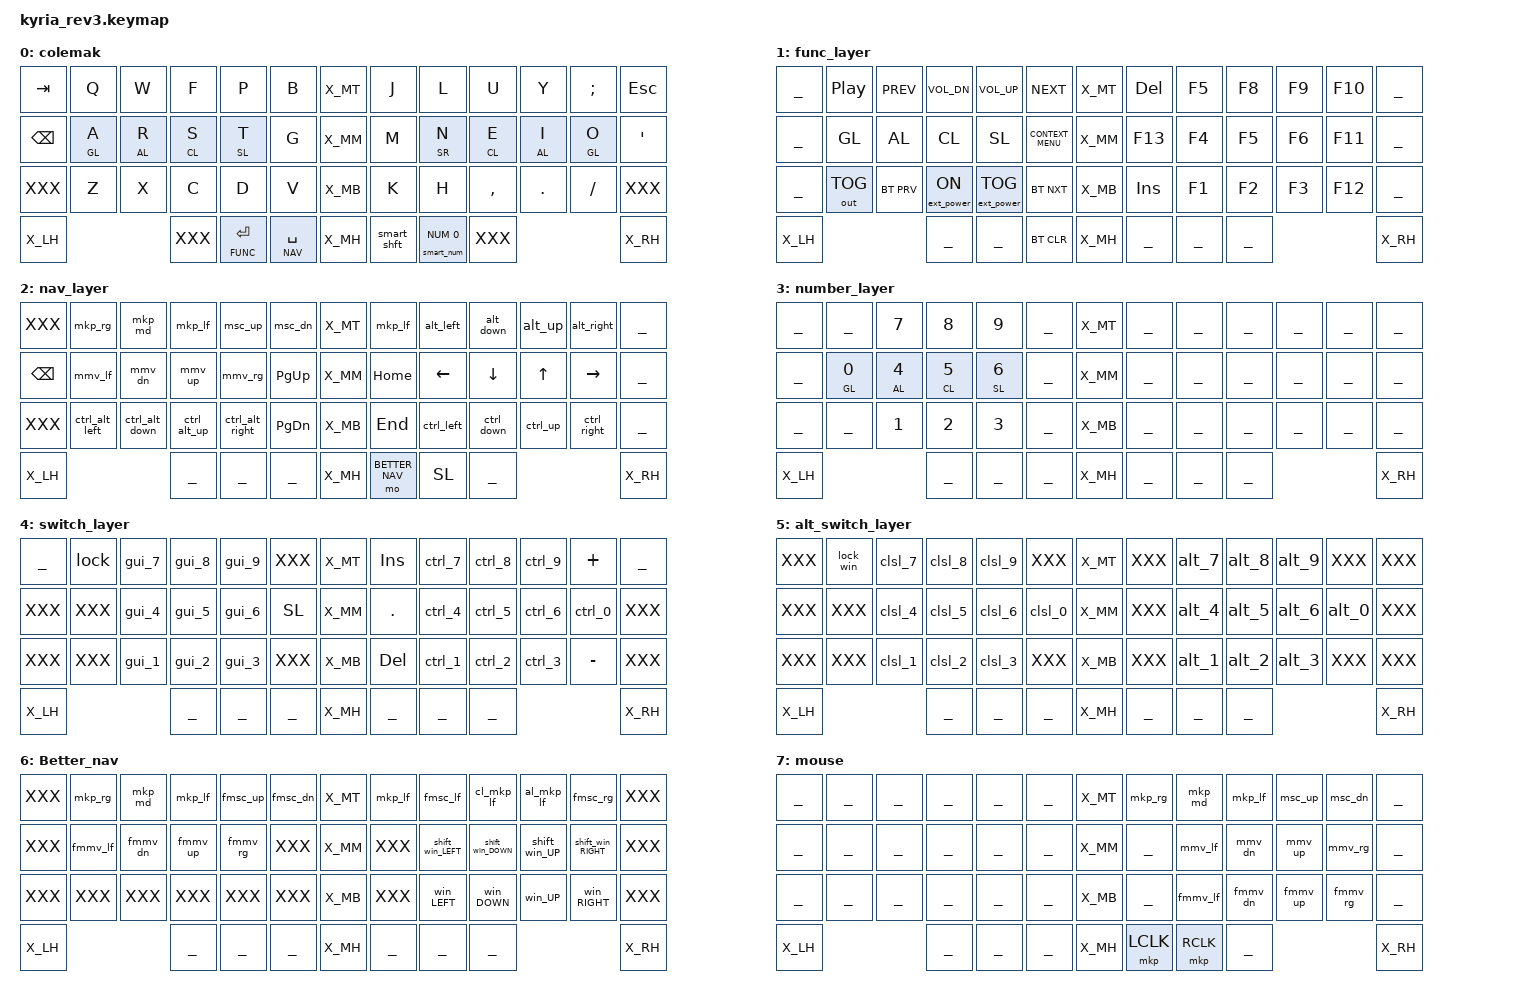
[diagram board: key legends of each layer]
/*      
 * Copyright (c) 2023 The ZMK Contributors
 *      vim.api.nvim_create_autocmd({ "BufRead", "BufNewFile" }, {
  pattern = "*.keymap",
  command = "set filetype=cpp",
})

 * SPDX-License-Identifier: MIT
 */

#include <behaviors.dtsi>
#include <dt-bindings/zmk/keys.h>
#include <dt-bindings/zmk/bt.h>
#include <dt-bindings/zmk/outputs.h>
#include <dt-bindings/zmk/mouse.h>
#include <dt-bindings/zmk/ext_power.h>
#include "extra_keys.h"

#include <dt-bindings/zmk/rgb.h>
#include "constants.h"
#define HOST_OS LINUX // Needed for unicode international_chars

#include "../zmk-nodefree-config/helper.h"
#include "../layouts/col_main.dtsi"
#include "../behaviors/combos_50.dtsi"
#include "../behaviors/hold-tap.dtsi"
#include "../behaviors/macros.dtsi"
#include "../behaviors/mod-morph.dtsi"
#include "../behaviors/mouse.dtsi"

/* map kyria's extra keys */
#define X_MT                    // top row, middle
#define X_MM                    // middle row, middle
#define X_MB  XXX XXX XXX XXX                 // bottom row, middle
#define X_LH  XXX XXX  // thumb row, left
#define X_RH  XXX XXX          // thumb row, right
/* Nav cluster */

// long-tap action on hold, short-tap action on all interrupts
#define MT_CORE \
    flavor = "tap-preferred"; \
    tapping-term-ms = <220>; \
    quick-tap-ms = <220>; \
    hold-trigger-key-positions = <0>;

&mt { MT_CORE };
ZMK_BEHAVIOR(mt_home, hold_tap, bindings = <&masked_home>, <&kp>; MT_CORE)
ZMK_BEHAVIOR(mt_end,  hold_tap,  bindings = <&masked_end>, <&kp>; MT_CORE)

#define NAV_LEFT  &mt_home 0   LEFT    // tap: left  | long-tap: beginning of line
#define NAV_RIGHT &mt_end 0    RIGHT   // tap: right | long-tap: end       of line
#define NAV_UP    &mt LC(HOME) UP      // tap: up    | long-tap: beginning of document
#define NAV_DOWN  &mt LC(END)  DOWN    // tap: down  | long-tap: end       of document
#define NAV_BSPC  &mt LC(BSPC) BSPC    // tap: bspc  | long-tap: delete word backward
#define NAV_DEL   &mt LC(DEL)  DEL     // tap: del   | long-tap: delete word forward

// mask CTRL when holding left/right to avoid accidental jumps to beginning/end of document
#define MASK_MODS(NAME, MODS, BINDING) \
    ZMK_BEHAVIOR(NAME, mod_morph, \
        bindings = <BINDING>, <BINDING>; \
        mods = <MODS>; \
    )
MASK_MODS(masked_home, (MOD_LCTL), &kp HOME)
MASK_MODS(masked_end,  (MOD_LCTL), &kp END)



/* Global settings */


&sk {  // sticky-key config
    release-after-ms = <900>;  // release after 0.6s
    quick-release;             // no double capitalization when rolling keys
};

&sl {  // sticky-layer config
    ignore-modifiers;          // allow chording sticky mods & layers
};


/* Homerow mods */

#define KEYS_L LT0 LT1 LT2 LT3 LT4 LM0 LM1 LM2 LM3 LM4 LB0 LB1 LB2 LB3 LB4  // left hand
#define KEYS_R RT0 RT1 RT2 RT3 RT4 RM0 RM1 RM2 RM3 RM4 RB0 RB1 RB2 RB3 RB4  // right hand
#define THUMBS LH2 LH1 LH0 RH0 RH1 RH2                                      // thumbs




#define QUICK_TAP_MS 175

&num_word {  // num-word, requires PR #1451
    layers = <NUM>;
    continue-list = <BSPC DEL DOT COMMA PLUS MINUS STAR FSLH EQUAL>;
};


ZMK_BEHAVIOR(num_dance, tap_dance,
    tapping-term-ms = <200>;
    bindings = <&num_word>, <&sl NUM>;  // reverse this for sticky-num on single tap
)

#define SMART_NUM &smart_num NUM 0
#// tap: num-word | double-tap: sticky num-layer | hold: num-layer
ZMK_BEHAVIOR(smart_num, hold_tap,
    flavor = "balanced";
    tapping-term-ms = <200>;
    quick-tap-ms = <QUICK_TAP_MS>;
    bindings = <&mo>, <&num_dance>;
)


ZMK_LAYER(colemak,
//╭──────╮ ╭─────────────┬─────────────┬─────────────┬─────────────┬─────────────╮ ╭──────╮ ╭─────────────┬─────────────┬─────────────┬─────────────┬─────────────╮ ╭──────╮
 &kp TAB     &kp Q         &kp W         &kp F         &kp P         &kp B           X_MT        &kp J       &kp L         &kp U        &kp Y         &kp SEMI      &kp ESC
//├──────┤ ├─────────────┼─────────────┼─────────────┼─────────────┼─────────────┤ ├──────┤ ├─────────────┼─────────────┼─────────────┼─────────────┼─────────────┤ ├──────┤
&kp BSPC    &hml GL A    &hml AL R      &hml CL S      &hml SL T     &kp G           X_MM        &kp M       &hmr SR N     &hmr CL E    &hmr AL I     &hml GL O     &kp SQT 
//├──────┤ ├─────────────┼─────────────┼─────────────┼─────────────┼─────────────┤ ├──────┤ ├─────────────┼─────────────┼─────────────┼─────────────┼─────────────┤ ├──────┤
    XXX         &kp Z        &kp X       &kp C         &kp D         &kp V           X_MB        &kp K       &kp H         &kp COMMA     &kp DOT      &kp FSLH        XXX
//├──────┤ ╰─────────────┼─────────────┴─────────────┼─────────────┼─────────────┤ ├──────┤ ├─────────────┼─────────────┼─────────────┴───────────────────────────╯ ├──────┤
    X_LH                                 XXX        &lt FUNC RETURN &lt NAV SPACE    X_MH      &smart_shft   SMART_NUM    XXX                                         X_RH
//╰──────╯                                           ╰─────────────┴─────────────╯ ╰──────╯ ╰─────────────┴─────────────╯                                           ╰──────╯
)


ZMK_LAYER(func_layer,
//╭──────╮ ╭─────────────┬─────────────┬─────────────┬─────────────┬─────────────╮ ╭──────╮ ╭─────────────┬─────────────┬─────────────┬─────────────┬─────────────╮ ╭──────╮
    ___     &kp C_PP       &kp C_PREV    &kp C_VOL_DN  &kp C_VOL_UP  &kp C_NEXT     X_MT      &kp DEL       &kp F5          &kp F8        &kp F9        &kp F10       ___
//├──────┤ ├─────────────┼─────────────┼─────────────┼─────────────┼─────────────┤ ├──────┤ ├─────────────┼─────────────┼─────────────┼─────────────┼─────────────┤ ├──────┤
    ___     &kp GL          &kp AL       &kp CL        &kp SL   &kp K_CONTEXT_MENU  X_MM      &kp F13       &kp F4          &kp F5        &kp F6        &kp F11       ___        
//├──────┤ ├─────────────┼─────────────┼─────────────┼─────────────┼─────────────┤ ├──────┤ ├─────────────┼─────────────┼─────────────┼─────────────┼─────────────┤ ├──────┤
    ___   &out OUT_TOG &bt BT_PRV   &ext_power EP_ON &ext_power EP_TOG &bt BT_NXT    X_MB      &kp INS       &kp F1          &kp F2        &kp F3        &kp F12       ___
//├──────┤ ╰─────────────┼─────────────┴─────────────┼─────────────┼─────────────┤ ├──────┤ ├─────────────┼─────────────┼─────────────┴───────────────────────────╯ ├──────┤
    X_LH                                ___           ___           &bt BT_CLR      X_MH       ___          ___           ___                                         X_RH
//╰──────╯                                           ╰─────────────┴─────────────╯ ╰──────╯ ╰─────────────┴─────────────╯                                           ╰──────╯
)

ZMK_LAYER(nav_layer,
//╭──────╮ ╭─────────────┬─────────────┬─────────────┬─────────────┬─────────────╮ ╭──────╮ ╭─────────────┬─────────────┬─────────────┬─────────────┬─────────────╮ ╭──────╮
    XXX      &mkp_rg        &mkp_md      &mkp_lf        &msc_up       &msc_dn        X_MT       &mkp_lf       &alt_left    &alt_down     &alt_up      &alt_right      ___
//├──────┤ ├─────────────┼─────────────┼─────────────┼─────────────┼─────────────┤ ├──────┤ ├─────────────┼─────────────┼─────────────┼─────────────┼─────────────┤ ├──────┤
&kp BSPC     &mmv_lf        &mmv_dn      &mmv_up        &mmv_rg       &kp PG_UP      X_MM    &kp HOME      &kp LEFT     &kp DOWN      &kp UP       &kp RIGHT       ___
//├──────┤ ├─────────────┼─────────────┼─────────────┼─────────────┼─────────────┤ ├──────┤ ├─────────────┼─────────────┼─────────────┼─────────────┼─────────────┤ ├──────┤
    XXX     &ctrl_alt_left &ctrl_alt_down &ctrl_alt_up &ctrl_alt_right &kp PG_DN     X_MB       &kp END       &ctrl_left   &ctrl_down    &ctrl_up     &ctrl_right     ___
//├──────┤ ╰─────────────┼─────────────┴─────────────┼─────────────┼─────────────┤ ├──────┤ ├─────────────┼─────────────┼─────────────┴───────────────────────────╯ ├──────┤
    X_LH                                ___           ___             ___            X_MH   &mo BETTER_NAV    &kp SL           ___                                    X_RH
//╰──────╯                                           ╰─────────────┴─────────────╯ ╰──────╯ ╰─────────────┴─────────────╯                                           ╰──────╯
)

                    
ZMK_LAYER(number_layer,
//╭──────╮ ╭─────────────┬─────────────┬─────────────┬─────────────┬─────────────╮ ╭──────╮ ╭─────────────┬─────────────┬─────────────┬─────────────┬─────────────╮ ╭──────╮
    ___          ___        &kp N7       &kp N8         &kp N9        ___            X_MT          ___           ___           ___           ___        ___           ___        
//├──────┤ ├─────────────┼─────────────┼─────────────┼─────────────┼─────────────┤ ├──────┤ ├─────────────┼─────────────┼─────────────┼─────────────┼─────────────┤ ├──────┤
    ___        &hml GL N0 &hml AL N4    &hml CL N5     &hml SL N6     ___            X_MM          ___           ___           ___           ___        ___           ___        
//├──────┤ ├─────────────┼─────────────┼─────────────┼─────────────┼─────────────┤ ├──────┤ ├─────────────┼─────────────┼─────────────┼─────────────┼─────────────┤ ├──────┤
    ___          ___        &kp N1      &kp N2         &kp N3         ___            X_MB          ___           ___           ___           ___        ___           ___   
//├──────┤ ╰─────────────┼─────────────┴─────────────┼─────────────┼─────────────┤ ├──────┤ ├─────────────┼─────────────┼─────────────┴───────────────────────────╯ ├──────┤
    X_LH                                ___           ___             ___            X_MH          ___           ___           ___                                    X_RH
//╰──────╯                                           ╰─────────────┴─────────────╯ ╰──────╯ ╰─────────────┴─────────────╯                                           ╰──────╯
)


ZMK_LAYER(switch_layer,
//╭──────╮ ╭─────────────┬─────────────┬─────────────┬─────────────┬─────────────╮ ╭──────╮ ╭─────────────┬─────────────┬─────────────┬─────────────┬─────────────╮ ╭──────╮
    ___         &lock       &gui_7       &gui_8         &gui_9        XXX            X_MT        &kp INS     &ctrl_7      &ctrl_8       &ctrl_9       &kp PLUS        ___
//├──────┤ ├─────────────┼─────────────┼─────────────┼─────────────┼─────────────┤ ├──────┤ ├─────────────┼─────────────┼─────────────┼─────────────┼─────────────┤ ├──────┤
    XXX         XXX         &gui_4       &gui_5         &gui_6       &kp SL          X_MM        &kp DOT     &ctrl_4       &ctrl_5         &ctrl_6        &ctrl_0     XXX
//├──────┤ ├─────────────┼─────────────┼─────────────┼─────────────┼─────────────┤ ├──────┤ ├─────────────┼─────────────┼─────────────┼─────────────┼─────────────┤ ├──────┤
    XXX         XXX         &gui_1       &gui_2         &gui_3        XXX            X_MB        &kp DEL     &ctrl_1       &ctrl_2      &ctrl_3       &kp MINUS       XXX
//├──────┤ ╰─────────────┼─────────────┴─────────────┼─────────────┼─────────────┤ ├──────┤ ├─────────────┼─────────────┼─────────────┴───────────────────────────╯ ├──────┤
    X_LH                                ___           ___             ___            X_MH          ___           ___           ___                                    X_RH
//╰──────╯                                           ╰─────────────┴─────────────╯ ╰──────╯ ╰─────────────┴─────────────╯                                           ╰──────╯
)


ZMK_LAYER(alt_switch_layer,
//╭──────╮ ╭─────────────┬─────────────┬─────────────┬─────────────┬─────────────╮ ╭──────╮ ╭─────────────┬─────────────┬─────────────┬─────────────┬─────────────╮ ╭──────╮
    XXX       &lock_win     &clsl_7      &clsl_8        &clsl_9       XXX            X_MT        XXX         &alt_7       &alt_8        &alt_9        XXX             XXX           
//├──────┤ ├─────────────┼─────────────┼─────────────┼─────────────┼─────────────┤ ├──────┤ ├─────────────┼─────────────┼─────────────┼─────────────┼─────────────┤ ├──────┤
    XXX       XXX           &clsl_4      &clsl_5        &clsl_6      &clsl_0         X_MM        XXX         &alt_4      &alt_5         &alt_6        &alt_0          XXX             
//├──────┤ ├─────────────┼─────────────┼─────────────┼─────────────┼─────────────┤ ├──────┤ ├─────────────┼─────────────┼─────────────┼─────────────┼─────────────┤ ├──────┤
    XXX       XXX           &clsl_1      &clsl_2        &clsl_3      XXX             X_MB        XXX         &alt_1      &alt_2         &alt_3        XXX             XXX             
//├──────┤ ╰─────────────┼─────────────┴─────────────┼─────────────┼─────────────┤ ├──────┤ ├─────────────┼─────────────┼─────────────┴───────────────────────────╯ ├──────┤
    X_LH                                ___           ___             ___            X_MH          ___           ___           ___                                    X_RH
//╰──────╯                                           ╰─────────────┴─────────────╯ ╰──────╯ ╰─────────────┴─────────────╯                                           ╰──────╯
)


ZMK_LAYER(Better_nav,
//╭──────╮ ╭─────────────┬─────────────┬─────────────┬─────────────┬─────────────╮ ╭──────╮ ╭─────────────┬─────────────┬─────────────┬─────────────┬─────────────╮ ╭──────╮
    XXX       &mkp_rg       &mkp_md      &mkp_lf        &fmsc_up      &fmsc_dn       X_MT       &mkp_lf      &fmsc_lf     &cl_mkp_lf    &al_mkp_lf    &fmsc_rg        XXX
//├──────┤ ├─────────────┼─────────────┼─────────────┼─────────────┼─────────────┤ ├──────┤ ├─────────────┼─────────────┼─────────────┼─────────────┼─────────────┤ ├──────┤
    XXX       &fmmv_lf      &fmmv_dn     &fmmv_up       &fmmv_rg     XXX             X_MM        XXX     &shift_win_LEFT &shift_win_DOWN &shift_win_UP &shift_win_RIGHT XXX
//├──────┤ ├─────────────┼─────────────┼─────────────┼─────────────┼─────────────┤ ├──────┤ ├─────────────┼─────────────┼─────────────┼─────────────┼─────────────┤ ├──────┤
    XXX       XXX           XXX          XXX            XXX          XXX             X_MB        XXX          &win_LEFT    &win_DOWN      &win_UP     &win_RIGHT      XXX
//├──────┤ ╰─────────────┼─────────────┴─────────────┼─────────────┼─────────────┤ ├──────┤ ├─────────────┼─────────────┼─────────────┴───────────────────────────╯ ├──────┤
    X_LH                                ___           ___             ___            X_MH          ___           ___           ___                                    X_RH
//╰──────╯                                           ╰─────────────┴─────────────╯ ╰──────╯ ╰─────────────┴─────────────╯                                           ╰──────╯
)

ZMK_LAYER(mouse,
//╭──────╮ ╭─────────────┬─────────────┬─────────────┬─────────────┬─────────────╮ ╭──────╮ ╭─────────────┬─────────────┬─────────────┬─────────────┬─────────────╮ ╭──────╮
    ___     ___           ___           ___           ___           ___             X_MT     &mkp_rg        &mkp_md        &mkp_lf       &msc_up     &msc_dn        ___
//├──────┤ ├─────────────┼─────────────┼─────────────┼─────────────┼─────────────┤ ├──────┤ ├─────────────┼─────────────┼─────────────┼─────────────┼─────────────┤ ├──────┤
    ___     ___           ___           ___           ___           ___             X_MM     ___           &mmv_lf       &mmv_dn        &mmv_up       &mmv_rg          ___
//├──────┤ ├─────────────┼─────────────┼─────────────┼─────────────┼─────────────┤ ├──────┤ ├─────────────┼─────────────┼─────────────┼─────────────┼─────────────┤ ├──────┤
    ___     ___           ___           ___           ___           ___             X_MB     ___           &fmmv_lf      &fmmv_dn       &fmmv_up      &fmmv_rg          ___
//├──────┤ ╰─────────────┼─────────────┴─────────────┼─────────────┼─────────────┤ ├──────┤ ├─────────────┼─────────────┼─────────────┴───────────────────────────╯ ├──────┤
    X_LH                                ___           ___           ___              X_MH     &mkp LCLK     &mkp RCLK     ___                                         X_RH
//╰──────╯                                           ╰─────────────┴─────────────╯ ╰──────╯ ╰─────────────┴─────────────╯                                           ╰──────╯
)



